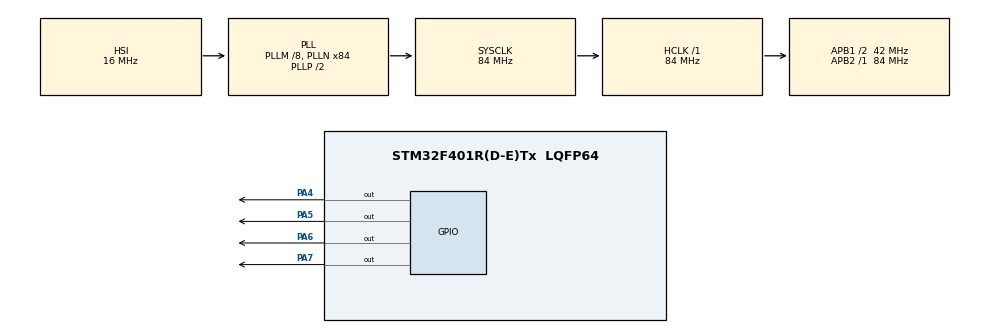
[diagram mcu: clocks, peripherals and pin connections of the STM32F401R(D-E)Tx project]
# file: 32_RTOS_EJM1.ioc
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FREERTOS.Tasks01=defaultTask,0,128,StartDefaultTask,Default,NULL,Dynamic,NULL,NULL;Tarea1,0,128,vTarea1,Default,NULL,Dynamic,NULL,NULL;Tarea2,0,128,vTarea2,Default,NULL,Dynamic,NULL,NULL;Tarea3,0,128,vTarea3,Default,NULL,Dynamic,NULL,NULL
FREERTOS.configENABLE_FPU=1
Mcu.Family=STM32F4
Mcu.Name=STM32F401R(D-E)Tx
Mcu.Package=LQFP64
NVIC.PriorityGroup=NVIC_PRIORITYGROUP_4
NVIC.TIM2_IRQn=true\:15\:0\:false\:false\:true\:false\:false\:true\:true
NVIC.TimeBase=TIM2_IRQn
NVIC.TimeBaseIP=TIM2
PA13.Mode=Serial_Wire
PA13.Signal=SYS_JTMS-SWDIO
PA14.Mode=Serial_Wire
PA14.Signal=SYS_JTCK-SWCLK
PA4.Signal=GPIO_Output
PA5.Signal=GPIO_Output
PA6.Signal=GPIO_Output
PA7.Signal=GPIO_Output
PH0\ -\ OSC_IN.Mode=HSE-External-Clock-Source
PH0\ -\ OSC_IN.Signal=RCC_OSC_IN
PH1\ -\ OSC_OUT.Mode=HSE-External-Clock-Source
PH1\ -\ OSC_OUT.Signal=RCC_OSC_OUT
ProjectManager.HeapSize=0x200
ProjectManager.StackSize=0x400
ProjectManager.TargetToolchain=STM32CubeIDE
RCC.48MHZClocksFreq_Value=42000000
RCC.AHBFreq_Value=84000000
RCC.APB1CLKDivider=RCC_HCLK_DIV2
RCC.APB1Freq_Value=42000000
RCC.APB1TimFreq_Value=84000000
RCC.APB2Freq_Value=84000000
RCC.APB2TimFreq_Value=84000000
RCC.CortexFreq_Value=84000000
RCC.HCLKFreq_Value=84000000
RCC.HSE_VALUE=8000000
RCC.HSI_VALUE=16000000
RCC.LSE_VALUE=32768
RCC.PLLM=8
RCC.PLLN=84
RCC.SYSCLKFreq_VALUE=84000000
RCC.SYSCLKSource=RCC_SYSCLKSOURCE_PLLCLK
RCC.VCOOutputFreq_Value=168000000
VP_FREERTOS_VS_CMSIS_V1.Mode=CMSIS_V1
VP_SYS_VS_tim2.Mode=TIM2
board=custom

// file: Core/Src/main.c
/* USER CODE BEGIN Header */
/**
  ******************************************************************************
  * @file           : main.c
  * @brief          : Main program body
  ******************************************************************************
  * @attention
  *
  * Copyright (c) 2024 STMicroelectronics.
  * All rights reserved.
  *
  * This software is licensed under terms that can be found in the LICENSE file
  * in the root directory of this software component.
  * If no LICENSE file comes with this software, it is provided AS-IS.
  *
  ******************************************************************************
  */
/* USER CODE END Header */
#include "main.h"
#include "cmsis_os.h"

osThreadId defaultTaskHandle;
osThreadId Tarea1Handle;
osThreadId Tarea2Handle;
osThreadId Tarea3Handle;

void SystemClock_Config(void);
static void MX_GPIO_Init(void);
void StartDefaultTask(void const * argument);
void vTarea1(void const * argument);
void vTarea2(void const * argument);
void vTarea3(void const * argument);

int main(void)
{

  /* MCU Configuration--------------------------------------------------------*/

  /* Reset of all peripherals, Initializes the Flash interface and the Systick. */
  HAL_Init();

  /* Configure the system clock */
  SystemClock_Config();

  /* Initialize all configured peripherals */
  MX_GPIO_Init();

  /* Create the thread(s) */
  /* definition and creation of defaultTask */
  osThreadDef(defaultTask, StartDefaultTask, osPriorityNormal, 0, 128);
  defaultTaskHandle = osThreadCreate(osThread(defaultTask), NULL);

  /* definition and creation of Tarea1 */
  osThreadDef(Tarea1, vTarea1, osPriorityNormal, 0, 128);
  Tarea1Handle = osThreadCreate(osThread(Tarea1), NULL);

  /* definition and creation of Tarea2 */
  osThreadDef(Tarea2, vTarea2, osPriorityNormal, 0, 128);
  Tarea2Handle = osThreadCreate(osThread(Tarea2), NULL);

  /* definition and creation of Tarea3 */
  osThreadDef(Tarea3, vTarea3, osPriorityNormal, 0, 128);
  Tarea3Handle = osThreadCreate(osThread(Tarea3), NULL);

  /* Start scheduler */
  osKernelStart();

  /* We should never get here as control is now taken by the scheduler */
  /* Infinite loop */
  while (1)
  {

  }
}

void SystemClock_Config(void)
{
  RCC_OscInitTypeDef RCC_OscInitStruct = {0};
  RCC_ClkInitTypeDef RCC_ClkInitStruct = {0};

  /** Configure the main internal regulator output voltage
  */
  __HAL_RCC_PWR_CLK_ENABLE();
  __HAL_PWR_VOLTAGESCALING_CONFIG(PWR_REGULATOR_VOLTAGE_SCALE2);

  /** Initializes the RCC Oscillators according to the specified parameters
  * in the RCC_OscInitTypeDef structure.
  */
  RCC_OscInitStruct.OscillatorType = RCC_OSCILLATORTYPE_HSI;
  RCC_OscInitStruct.HSIState = RCC_HSI_ON;
  RCC_OscInitStruct.HSICalibrationValue = RCC_HSICALIBRATION_DEFAULT;
  RCC_OscInitStruct.PLL.PLLState = RCC_PLL_ON;
  RCC_OscInitStruct.PLL.PLLSource = RCC_PLLSOURCE_HSI;
  RCC_OscInitStruct.PLL.PLLM = 8;
  RCC_OscInitStruct.PLL.PLLN = 84;
  RCC_OscInitStruct.PLL.PLLP = RCC_PLLP_DIV2;
  RCC_OscInitStruct.PLL.PLLQ = 4;
  if (HAL_RCC_OscConfig(&RCC_OscInitStruct) != HAL_OK)
  {
    Error_Handler();
  }

  /** Initializes the CPU, AHB and APB buses clocks
  */
  RCC_ClkInitStruct.ClockType = RCC_CLOCKTYPE_HCLK|RCC_CLOCKTYPE_SYSCLK
                              |RCC_CLOCKTYPE_PCLK1|RCC_CLOCKTYPE_PCLK2;
  RCC_ClkInitStruct.SYSCLKSource = RCC_SYSCLKSOURCE_PLLCLK;
  RCC_ClkInitStruct.AHBCLKDivider = RCC_SYSCLK_DIV1;
  RCC_ClkInitStruct.APB1CLKDivider = RCC_HCLK_DIV2;
  RCC_ClkInitStruct.APB2CLKDivider = RCC_HCLK_DIV1;

  if (HAL_RCC_ClockConfig(&RCC_ClkInitStruct, FLASH_LATENCY_2) != HAL_OK)
  {
    Error_Handler();
  }
}

static void MX_GPIO_Init(void)
{
  GPIO_InitTypeDef GPIO_InitStruct = {0};

  /* GPIO Ports Clock Enable */
  __HAL_RCC_GPIOH_CLK_ENABLE();
  __HAL_RCC_GPIOA_CLK_ENABLE();

  /*Configure GPIO pin Output Level */
  HAL_GPIO_WritePin(GPIOA, GPIO_PIN_4|GPIO_PIN_5|GPIO_PIN_6|GPIO_PIN_7, GPIO_PIN_RESET);

  /*Configure GPIO pins : PA4 PA5 PA6 PA7 */
  GPIO_InitStruct.Pin = GPIO_PIN_4|GPIO_PIN_5|GPIO_PIN_6|GPIO_PIN_7;
  GPIO_InitStruct.Mode = GPIO_MODE_OUTPUT_PP;
  GPIO_InitStruct.Pull = GPIO_NOPULL;
  GPIO_InitStruct.Speed = GPIO_SPEED_FREQ_LOW;
  HAL_GPIO_Init(GPIOA, &GPIO_InitStruct);

}

void StartDefaultTask(void const * argument)
{
  /* USER CODE BEGIN 5 */
  /* Infinite loop */
  for(;;)
  {
	  GPIOA->ODR ^=  (1<<5);
	  osDelay(200);
  }
  /* USER CODE END 5 */
}

void vTarea1(void const * argument)
{
  /* USER CODE BEGIN vTarea1 */
  /* Infinite loop */
  for(;;)
  {
	  GPIOA->ODR ^=  (1<<6);
	  osDelay(150);
  }
  /* USER CODE END vTarea1 */
}

void vTarea2(void const * argument)
{
  /* USER CODE BEGIN vTarea2 */
  /* Infinite loop */
  for(;;)
  {
	  GPIOA->ODR ^=  (1<<7);
	  osDelay(300);
  }
  /* USER CODE END vTarea2 */
}

void vTarea3(void const * argument)
{
  /* USER CODE BEGIN vTarea3 */
  /* Infinite loop */
  for(;;)
  {
	  GPIOA->ODR ^=  (1<<4);
	  osDelay(100);
  }
  /* USER CODE END vTarea3 */
}

void HAL_TIM_PeriodElapsedCallback(TIM_HandleTypeDef *htim)
{
  if (htim->Instance == TIM2) {
    HAL_IncTick();
  }
}

void Error_Handler(void)
{
  __disable_irq();
  while (1)
  {
  }
}
